VERSION ""

NS_ :

BS_: 500

BU_: Vector__XXX

BO_ 512 MSG_200: 8 Vector__XXX
 SG_ Wheel_Speed_FR_kph : 16|14@0+ (0.0625,0) [0|8191] "km/h" Vector__XXX
 SG_ Wheel_Speed_FR_mph : 16|14@0+ (0.0388125,0) [0|5086.611] "mph" Vector__XXX
 SG_ Wheel_Speed_FL_kph : 32|14@0+ (0.0625,0) [0|8191] "km/h" Vector__XXX
 SG_ Wheel_Speed_FL_mph : 32|14@0+ (0.0388125,0) [0|5086.611] "mph" Vector__XXX

BO_ 520 MSG_208: 8 Vector__XXX
 SG_ Wheel_Speed_RL : 0|14@0+ (0.5,0) [0|8191] "rpm" Vector__XXX
 SG_ Wheel_Speed_RR : 16|14@0+ (0.5,0) [0|8191] "rpm" Vector__XXX

BO_ 528 MSG_210: 8 Vector__XXX
 SG_ Accelerator_Pedal_Position : 16|8@1+ (0.4,0) [0|100] "%" Vector__XXX

BO_ 533 MSG_215: 7 Vector__XXX
 SG_ Indicated_Vehicle_Speed_kph : 48|16@0+ (0.0078125,0) [0|511.99] "km/h" Vector__XXX
 SG_ Indicated_Vehicle_Speed_mph : 48|16@0+ (0.0048515625,0) [0|317.94579] "mph" Vector__XXX

BO_ 566 MSG_236: 8 Vector__XXX
 SG_ Steering_Rate : 32|14@0+ (0.5,-2048) [-2048|2047] "��/s" Vector__XXX
 SG_ Steering_Angle : 48|14@0+ (0.5,-2048) [-2048|2047] "��" Vector__XXX

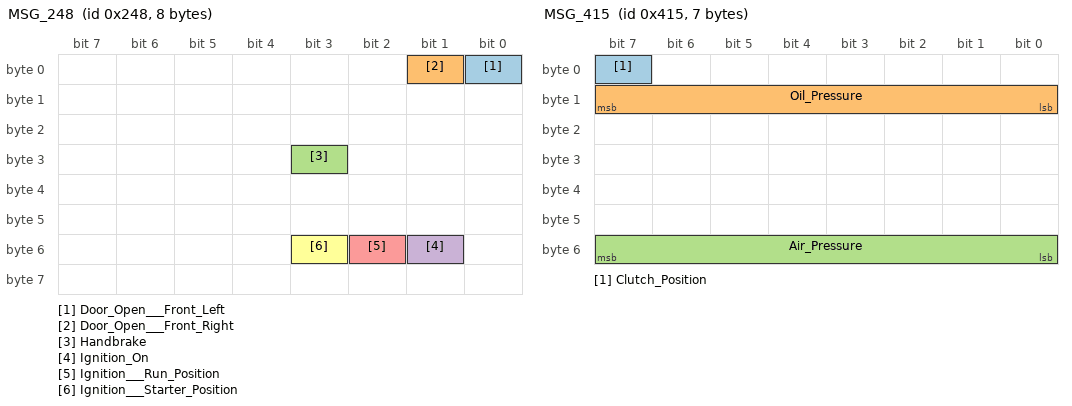
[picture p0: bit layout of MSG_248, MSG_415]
BO_ 584 MSG_248: 8 Vector__XXX
 SG_ Door_Open___Front_Left : 0|1@1+ (1,0) [0|0] "" Vector__XXX
 SG_ Door_Open___Front_Right : 1|1@1+ (1,0) [0|0] "" Vector__XXX
 SG_ Handbrake : 27|1@1+ (1,0) [0|0] "on/off" Vector__XXX
 SG_ Ignition_On : 49|1@1+ (1,0) [0|0] "on/off" Vector__XXX
 SG_ Ignition___Run_Position : 50|1@1+ (1,0) [0|0] "on/off" Vector__XXX
 SG_ Ignition___Starter_Position : 51|1@1+ (1,0) [0|0] "on/off" Vector__XXX

BO_ 768 MSG_300: 8 Vector__XXX
 SG_ Yaw_Rate : 0|16@0+ (0.01,-327.68) [-327.68|327.66] "��/s" Vector__XXX

BO_ 776 MSG_308: 8 Vector__XXX
 SG_ Engine_Speed : 40|16@0+ (1,0) [0|65534] "rpm" Vector__XXX
 SG_ Oil_Temperature : 40|8@1+ (1,-40) [-40|160] "��C" Vector__XXX

BO_ 789 MSG_315: 6 Vector__XXX
 SG_ Brake_Position : 0|2@1+ (1,0) [0|0] "" Vector__XXX
 SG_ Battery_Voltage : 40|8@1+ (0.1,0) [5|18] "V" Vector__XXX

BO_ 805 MSG_325: 7 Vector__XXX
 SG_ Odometer_Reading : 32|24@0+ (0.1,0) [0|1677721.4] "km" Vector__XXX

BO_ 808 MSG_328: 8 Vector__XXX
 SG_ Indicated_Lateral_Acceleration : 16|8@1+ (0.08,-10.24) [-10.24|10.08] "m/s��" Vector__XXX

BO_ 816 MSG_330: 8 Vector__XXX
 SG_ Indicated_Longitudinal_Acceleration : 56|8@1+ (0.08,-10.24) [-10.24|10.08] "m/s��" Vector__XXX

BO_ 1023 MSG_3FF: 6 Vector__XXX
 SG_ Headlights : 10|1@1+ (1,0) [0|0] "on/off" Vector__XXX
 SG_ Full_Beam : 11|1@1+ (1,0) [0|0] "on/off" Vector__XXX

BO_ 1032 MSG_408: 8 Vector__XXX
 SG_ Air_Temperature : 16|8@1+ (0.5,-40) [-40|85] "��C" Vector__XXX

BO_ 1045 MSG_415: 7 Vector__XXX
 SG_ Clutch_Position : 7|1@1+ (1,0) [0|0] "on/off" Vector__XXX
 SG_ Oil_Pressure : 8|8@1+ (4,0) [0|1016] "kPaG" Vector__XXX
 SG_ Air_Pressure : 48|8@1+ (1,0) [0|254] "kPa" Vector__XXX

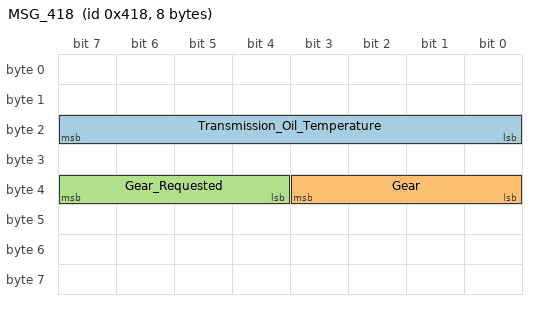
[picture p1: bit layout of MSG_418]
BO_ 1048 MSG_418: 8 Vector__XXX
 SG_ Transmission_Oil_Temperature : 16|8@1+ (1,-50) [-50|204] "��C" Vector__XXX
 SG_ Gear : 32|4@1+ (1,0) [0|0] "" Vector__XXX
 SG_ Gear_Requested : 36|4@1+ (1,0) [0|0] "" Vector__XXX

BO_ 1184 MSG_4A0: 8 Vector__XXX
 SG_ Throttle_Position : 40|8@1+ (0.019607843,0) [0|4.98] "V" Vector__XXX

BO_ 1544 MSG_608: 8 Vector__XXX
 SG_ Coolant_Temperature : 0|8@1+ (1,-40) [-40|214] "��C" Vector__XXX
 SG_ Fuel_Consumption : 8|16@0+ (0.217,0) [0|14200] "" Vector__XXX
 SG_ Intake_Air_Temperature : 8|8@1+ (1,-40) [-40|214] "��C" Vector__XXX
